# PY32F403xx register map
Vendor: PUYA Co.Ltd; Series: ARMCM4; File version: 1.2
CPU: CM4 r0p1, little endian, MPU, FPU, 4 interrupt priority bits
Registers are 32-bit, read-write, reset 0x0 unless marked. A register's access mark holds for its fields unless they carry their own. Offsets are from the block's base; [hi:lo] are bit positions; {n}, {i} and the like mark numbered series; 'fields as' and 'values as' point back to an identical list.

## CRC
Base 0x40023000
0x00 DR
0x04 IDR
  [7:0] IDR
0x08 CR
  [0] RESET

## CTC
Base 0x4000C800
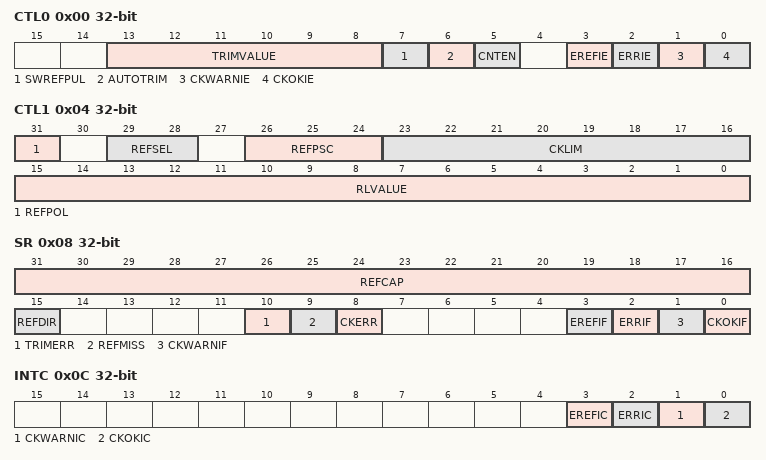
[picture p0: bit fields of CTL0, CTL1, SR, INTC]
0x00 CTL0
  [13:8] TRIMVALUE, [7] SWREFPUL, [6] AUTOTRIM, [5] CNTEN, [3] EREFIE, [2] ERRIE, [1] CKWARNIE, [0] CKOKIE
0x04 CTL1
  [31] REFPOL
  [29:28] REFSEL
    1=0; 2=1
  [26:24] REFPSC
    1=0; 2=1; 4=2
  [23:16] CKLIM
  [15:0] RLVALUE
0x08 SR
  [31:16] REFCAP ro, [15] REFDIR ro, [10] TRIMERR ro, [9] REFMISS ro, [8] CKERR ro, [3] EREFIF ro, [2] ERRIF ro, [1] CKWARNIF ro, [0] CKOKIF ro
0x0C INTC
  [3] EREFIC, [2] ERRIC, [1] CKWARNIC, [0] CKOKIC

## DAC
Base 0x40007400
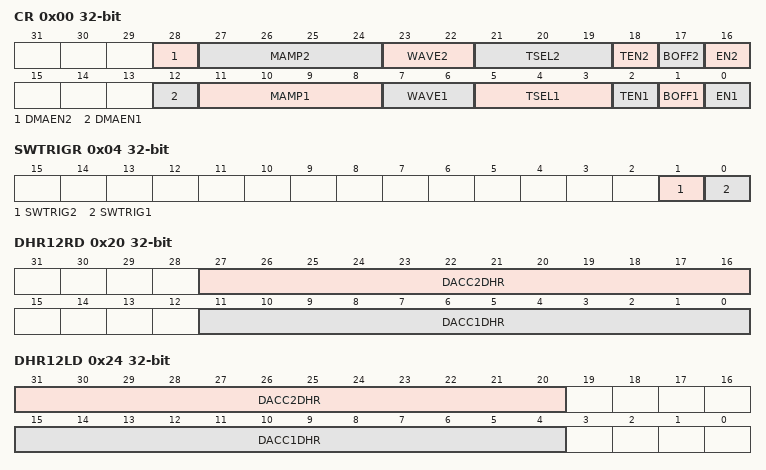
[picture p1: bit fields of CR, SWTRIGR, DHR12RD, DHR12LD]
0x00 CR
  [28] DMAEN2
  [27:24] MAMP2
    1=0; 2=1; 4=2; 8=3
  [23:22] WAVE2
    1=0; 2=1
  [21:19] TSEL2
    1=0; 2=1; 4=2
  [18] TEN2
  [17] BOFF2
  [16] EN2
  [12] DMAEN1
  [11:8] MAMP1
    1=0; 2=1; 4=2; 8=3
  [7:6] WAVE1
    1=0; 2=1
  [5:3] TSEL1
    1=0; 2=1; 4=2
  [2] TEN1
  [1] BOFF1
  [0] EN1
0x04 SWTRIGR
  [1] SWTRIG2, [0] SWTRIG1
0x08 DHR12R1
  [11:0] DACC1DHR ro
0x0C DHR12L1
  [14:3] DACC1DLR ro — desc DACC1DHR
0x10 DHR8R1
  [7:0] DACC1DHR ro
0x14 DHR12R2
  [11:0] DACC2DHR ro
0x18 DHR12L2
  [15:4] DACC2DHR ro
0x1C DHR8R2
  [7:0] DACC2DHR ro
0x20 DHR12RD
  [27:16] DACC2DHR ro, [11:0] DACC1DHR ro
0x24 DHR12LD
  [31:20] DACC2DHR ro, [15:4] DACC1DHR ro
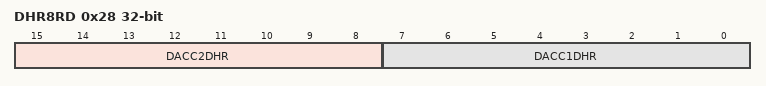
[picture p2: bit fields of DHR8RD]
0x28 DHR8RD
  [15:8] DACC2DHR ro, [7:0] DACC1DHR ro
0x2C DOR1
  [11:0] DACC1DOR ro
0x30 DOR2
  [11:0] DACC2DOR ro

## DBGMCU
Base 0xE0042000
0x00 IDCODE
  [31:0] REV_ID ro
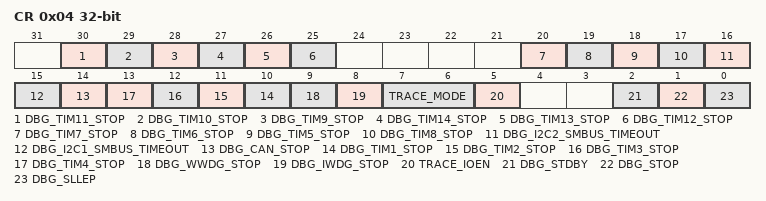
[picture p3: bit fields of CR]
0x04 CR
  [30] DBG_TIM11_STOP
  [29] DBG_TIM10_STOP
  [28] DBG_TIM9_STOP
  [27] DBG_TIM14_STOP
  [26] DBG_TIM13_STOP
  [25] DBG_TIM12_STOP
  [20] DBG_TIM7_STOP
  [19] DBG_TIM6_STOP
  [18] DBG_TIM5_STOP
  [17] DBG_TIM8_STOP
  [16] DBG_I2C2_SMBUS_TIMEOUT
  [15] DBG_I2C1_SMBUS_TIMEOUT
  [14] DBG_CAN_STOP
  [n+9] DBG_TIM{n}_STOP (n=1..4)
  [9] DBG_WWDG_STOP
  [8] DBG_IWDG_STOP
  [7:6] TRACE_MODE
    1=0; 2=1
  [5] TRACE_IOEN
  [2] DBG_STDBY
  [1] DBG_STOP
  [0] DBG_SLLEP

## DMA1 — desc DMA
Base 0x40020000
Same registers: DMA2 0x40020400
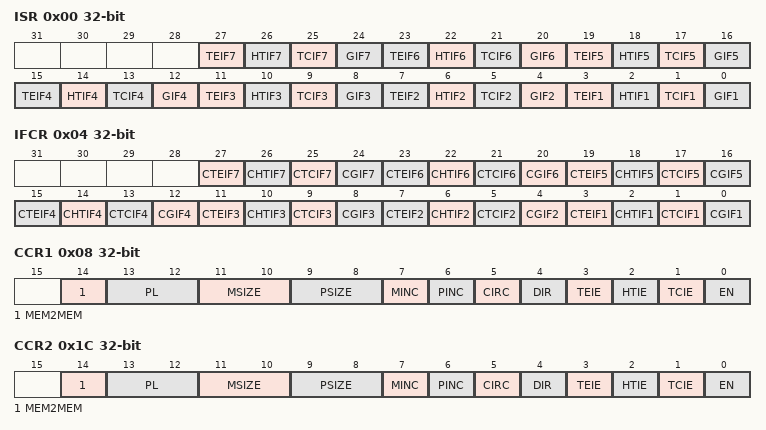
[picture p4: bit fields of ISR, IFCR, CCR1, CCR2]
0x00 ISR
  [4n-1] TEIF{n} ro (n=1..7), [4n-2] HTIF{n} ro (n=1..7), [4n-3] TCIF{n} ro (n=1..7), [4n-4] GIF{n} ro (n=1..7)
0x04 IFCR
  [4n-1] CTEIF{n} (n=1..7), [4n-2] CHTIF{n} (n=1..7), [4n-3] CTCIF{n} (n=1..7), [4n-4] CGIF{n} (n=1..7)
0x08 CCR1
  [14] MEM2MEM, [13:12] PL, [11:10] MSIZE, [9:8] PSIZE, [7] MINC, [6] PINC, [5] CIRC, [4] DIR, [3] TEIE, [2] HTIE, [1] TCIE, [0] EN
0x0C CNDTR1
  [15:0] NDT
0x10 CPAR1
  [31:0] PA
{0x0+0x14*i} CMAR{i} (i=1..7)
  [31:0] MA
0x1C CCR2
  fields as CCR1
0x20 CNDTR2
  [15:0] NDT
0x24 CPAR2
  [31:0] PA
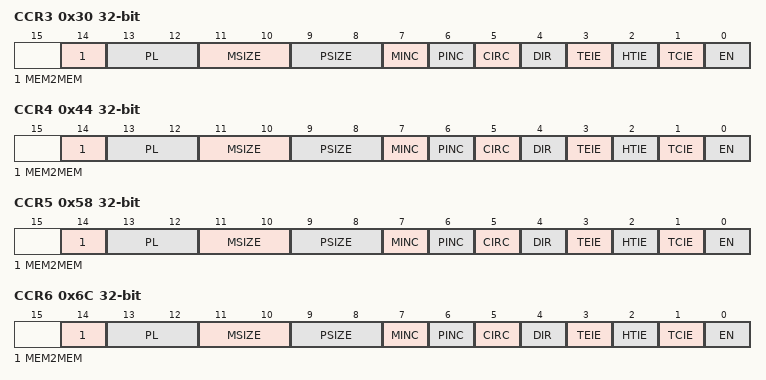
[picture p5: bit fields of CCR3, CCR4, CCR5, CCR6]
0x30 CCR3
  fields as CCR1
0x34 CNDTR3
  [15:0] NDT
0x38 CPAR3
  [31:0] PA
0x44 CCR4
  fields as CCR1
0x48 CNDTR4
  [15:0] NDT
0x4C CPAR4
  [31:0] PA
0x58 CCR5
  fields as CCR1
0x5C CNDTR5
  [15:0] NDT
0x60 CPAR5
  [31:0] PA
0x6C CCR6
  fields as CCR1
0x70 CNDTR6
  [15:0] NDT
0x74 CPAR6
  [31:0] PA
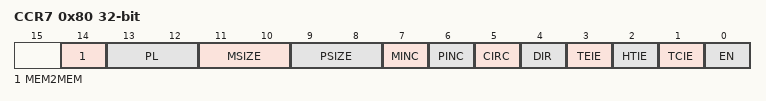
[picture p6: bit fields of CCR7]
0x80 CCR7
  fields as CCR1
0x84 CNDTR7
  [15:0] NDT
0x88 CPAR7
  [31:0] PA

## ESMC
Base 0xA0001000
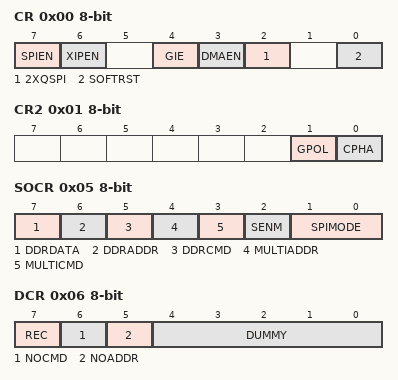
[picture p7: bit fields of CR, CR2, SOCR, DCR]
0x00 CR 8-bit
  [7] SPIEN, [6] XIPEN, [4] GIE, [3] DMAEN, [2] 2XQSPI, [0] SOFTRST
0x01 CR2 8-bit
  [1] GPOL — desc CPOL
  [0] CPHA
0x02 TCR 8-bit
  [7:0] TCR
    1=0; 2=1; 4=2; 8=3; 16=4; 32=5; 64=6; 128=7
0x03 BAUD 8-bit
  [7:0] BAUD
    1=0; 2=1; 4=2; 8=3; 16=4; 32=5; 64=6; 128=7
0x04 SFCR 8-bit
  [7:0] INS0
0x05 SOCR 8-bit
  [7] DDRDATA
  [6] DDRADDR
  [5] DDRCMD
  [4] MULTIADDR
  [3] MULTICMD
  [2] SENM
  [1:0] SPIMODE
    1=0; 2=1
0x06 DCR 8-bit
  [7] REC
  [6] NOCMD
  [5] NOADDR
  [4:0] DUMMY
    1=0; 2=1; 4=2; 8=3; 16=4
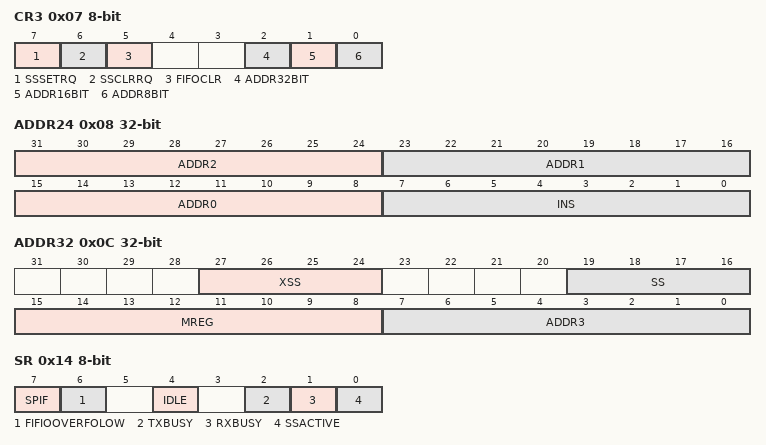
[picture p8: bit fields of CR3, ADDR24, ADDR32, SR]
0x07 CR3 8-bit
  [7] SSSETRQ, [6] SSCLRRQ, [5] FIFOCLR, [2] ADDR32BIT, [1] ADDR16BIT, [0] ADDR8BIT
0x08 ADDR24
  [all] fields
    1=0; 2=1; 4=2; 8=3; 16=4; 32=5; 64=6; 128=7
  [31:24] ADDR2
  [23:16] ADDR1
  [15:8] ADDR0
  [7:0] INS
0x0C ADDR32
  [27:24] XSS
  [19:16] SS
    1=0; 2=1; 4=2; 8=3
  [15:8] MREG
    1=0; 2=1; 4=2; 8=3; 16=4; 32=5; 64=6; 128=7
  [7:0] ADDR3
    1=0; 2=1; 4=2; 8=3; 16=4; 32=5; 64=6; 128=7
0x14 SR 8-bit
  [7] SPIF, [6] FIFIOOVERFOLOW, [4] IDLE, [2] TXBUSY, [1] RXBUSY, [0] SSACTIVE
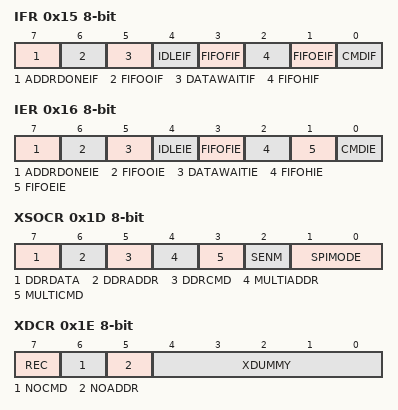
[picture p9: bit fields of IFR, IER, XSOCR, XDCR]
0x15 IFR 8-bit
  [7] ADDRDONEIF, [6] FIFOOIF, [5] DATAWAITIF, [4] IDLEIF, [3] FIFOFIF, [2] FIFOHIF, [1] FIFOEIF, [0] CMDIF
0x16 IER 8-bit
  [7] ADDRDONEIE, [6] FIFOOIE, [5] DATAWAITIE, [4] IDLEIE, [3] FIFOFIE, [2] FIFOHIE, [1] FIFOEIE, [0] CMDIE
0x1C XSFCR 8-bit
  [7:0] XINS
0x1D XSOCR 8-bit
  [7] DDRDATA, [6] DDRADDR, [5] DDRCMD, [4] MULTIADDR, [3] MULTICMD, [2] SENM, [1:0] SPIMODE
0x1E XDCR 8-bit — desc DCR
  [7] REC, [6] NOCMD, [5] NOADDR, [4:0] XDUMMY
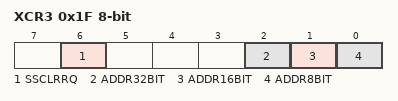
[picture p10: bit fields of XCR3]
0x1F XCR3 8-bit
  [6] SSCLRRQ, [2] ADDR32BIT, [1] ADDR16BIT, [0] ADDR8BIT
